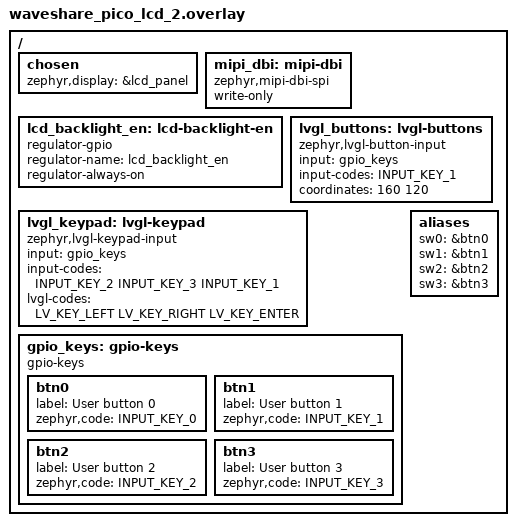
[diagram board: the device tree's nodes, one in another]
/*
 * SPDX-FileCopyrightText: Copyright (c) 2023-2026 TiaC Systems
 * SPDX-License-Identifier: Apache-2.0
 */

#include <zephyr/dt-bindings/input/input-event-codes.h>
#include <zephyr/dt-bindings/lvgl/lvgl.h>

/ {
	chosen {
		zephyr,display = &lcd_panel;
	};

	mipi_dbi: mipi-dbi {
		compatible = "zephyr,mipi-dbi-spi";
		write-only;
	};

	lcd_backlight_en: lcd-backlight-en {
		compatible = "regulator-gpio";
		regulator-name = "lcd_backlight_en";
		regulator-always-on;
	};

	lvgl_buttons: lvgl-buttons {
		compatible = "zephyr,lvgl-button-input";
		input = <&gpio_keys>;
		input-codes = <INPUT_KEY_1>;
		coordinates = <160 120>;
	};

	lvgl_keypad: lvgl-keypad {
		compatible = "zephyr,lvgl-keypad-input";
		input = <&gpio_keys>;
		input-codes = <INPUT_KEY_2 INPUT_KEY_3
			       INPUT_KEY_1>;
		lvgl-codes = <LV_KEY_LEFT LV_KEY_RIGHT
			      LV_KEY_ENTER>;
	};

	/delete-node/ gpio_keys;
	/delete-node/ gpio-keys;
	gpio_keys: gpio-keys {
		compatible = "gpio-keys";
		btn0: btn0 {
			label = "User button 0";
			zephyr,code = <INPUT_KEY_0>;
		};
		btn1: btn1 {
			label = "User button 1";
			zephyr,code = <INPUT_KEY_1>;
		};
		btn2: btn2 {
			label = "User button 2";
			zephyr,code = <INPUT_KEY_2>;
		};
		btn3: btn3 {
			label = "User button 3";
			zephyr,code = <INPUT_KEY_3>;
		};
	};

	aliases {
		/delete-property/ sw0;
		sw0 = &btn0;
		sw1 = &btn1;
		sw2 = &btn2;
		sw3 = &btn3;
	};
};
